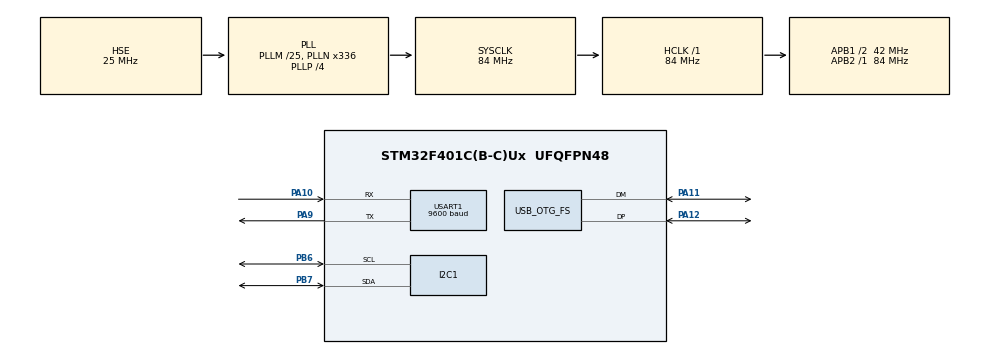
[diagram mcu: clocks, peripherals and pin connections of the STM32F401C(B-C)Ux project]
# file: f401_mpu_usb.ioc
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I2C1.I2C_Mode=I2C_Fast
Mcu.Family=STM32F4
Mcu.Name=STM32F401C(B-C)Ux
Mcu.Package=UFQFPN48
NVIC.OTG_FS_IRQn=true\:0\:0\:false\:false\:true\:false
NVIC.PriorityGroup=NVIC_PRIORITYGROUP_4
NVIC.USART1_IRQn=true\:0\:0\:false\:false\:true\:true
PA10.Mode=Asynchronous
PA10.Signal=USART1_RX
PA11.Mode=Device_Only
PA11.Signal=USB_OTG_FS_DM
PA12.Mode=Device_Only
PA12.Signal=USB_OTG_FS_DP
PA13.Mode=Serial_Wire
PA13.Signal=SYS_JTMS-SWDIO
PA14.Mode=Serial_Wire
PA14.Signal=SYS_JTCK-SWCLK
PA9.Mode=Asynchronous
PA9.Signal=USART1_TX
PB6.Mode=I2C
PB6.Signal=I2C1_SCL
PB7.Mode=I2C
PB7.Signal=I2C1_SDA
PH0\ -\ OSC_IN.Mode=HSE-External-Oscillator
PH0\ -\ OSC_IN.Signal=RCC_OSC_IN
PH1\ -\ OSC_OUT.Mode=HSE-External-Oscillator
PH1\ -\ OSC_OUT.Signal=RCC_OSC_OUT
ProjectManager.HeapSize=0x200
ProjectManager.StackSize=0x400
ProjectManager.TargetToolchain=SW4STM32
RCC.48MHZClocksFreq_Value=48000000
RCC.AHBFreq_Value=84000000
RCC.APB1CLKDivider=RCC_HCLK_DIV2
RCC.APB1Freq_Value=42000000
RCC.APB1TimFreq_Value=84000000
RCC.APB2Freq_Value=84000000
RCC.APB2TimFreq_Value=84000000
RCC.CortexFreq_Value=84000000
RCC.HCLKFreq_Value=84000000
RCC.HSE_VALUE=25000000
RCC.HSI_VALUE=16000000
RCC.LSE_VALUE=32768
RCC.PLLM=25
RCC.PLLN=336
RCC.PLLP=RCC_PLLP_DIV4
RCC.PLLQ=7
RCC.SYSCLKFreq_VALUE=84000000
RCC.SYSCLKSource=RCC_SYSCLKSOURCE_PLLCLK
RCC.VCOOutputFreq_Value=336000000
USART1.BaudRate=9600
USART1.VirtualMode=VM_ASYNC
USB_DEVICE.CLASS_NAME_FS=CDC
USB_DEVICE.VirtualMode=Cdc
USB_DEVICE.VirtualModeFS=Cdc_FS
USB_OTG_FS.VirtualMode=Device_Only
VP_USB_DEVICE_VS_USB_DEVICE_CDC_FS.Mode=CDC_FS
board=custom

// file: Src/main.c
/* USER CODE BEGIN Header */
/**
  ******************************************************************************
  * @file           : main.c
  * @brief          : Main program body
  ******************************************************************************
  * This notice applies to any and all portions of this file
  * that are not between comment pairs USER CODE BEGIN and
  * USER CODE END. Other portions of this file, whether
  * inserted by the user or by software development tools
  * are owned by their respective copyright owners.
  *
  * Copyright (c) 2020 STMicroelectronics International N.V.
  * All rights reserved.
  *
  * Redistribution and use in source and binary forms, with or without
  * modification, are permitted, provided that the following conditions are met:
  *
  * 1. Redistribution of source code must retain the above copyright notice,
  *    this list of conditions and the following disclaimer.
  * 2. Redistributions in binary form must reproduce the above copyright notice,
  *    this list of conditions and the following disclaimer in the documentation
  *    and/or other materials provided with the distribution.
  * 3. Neither the name of STMicroelectronics nor the names of other
  *    contributors to this software may be used to endorse or promote products
  *    derived from this software without specific written permission.
  * 4. This software, including modifications and/or derivative works of this
  *    software, must execute solely and exclusively on microcontroller or
  *    microprocessor devices manufactured by or for STMicroelectronics.
  * 5. Redistribution and use of this software other than as permitted under
  *    this license is void and will automatically terminate your rights under
  *    this license.
  *
  * THIS SOFTWARE IS PROVIDED BY STMICROELECTRONICS AND CONTRIBUTORS "AS IS"
  * AND ANY EXPRESS, IMPLIED OR STATUTORY WARRANTIES, INCLUDING, BUT NOT
  * LIMITED TO, THE IMPLIED WARRANTIES OF MERCHANTABILITY, FITNESS FOR A
  * PARTICULAR PURPOSE AND NON-INFRINGEMENT OF THIRD PARTY INTELLECTUAL PROPERTY
  * RIGHTS ARE DISCLAIMED TO THE FULLEST EXTENT PERMITTED BY LAW. IN NO EVENT
  * SHALL STMICROELECTRONICS OR CONTRIBUTORS BE LIABLE FOR ANY DIRECT, INDIRECT,
  * INCIDENTAL, SPECIAL, EXEMPLARY, OR CONSEQUENTIAL DAMAGES (INCLUDING, BUT NOT
  * LIMITED TO, PROCUREMENT OF SUBSTITUTE GOODS OR SERVICES; LOSS OF USE, DATA,
  * OR PROFITS; OR BUSINESS INTERRUPTION) HOWEVER CAUSED AND ON ANY THEORY OF
  * LIABILITY, WHETHER IN CONTRACT, STRICT LIABILITY, OR TORT (INCLUDING
  * NEGLIGENCE OR OTHERWISE) ARISING IN ANY WAY OUT OF THE USE OF THIS SOFTWARE,
  * EVEN IF ADVISED OF THE POSSIBILITY OF SUCH DAMAGE.
  *
  ******************************************************************************
  */
/* USER CODE END Header */

#include <usbd_cdc_if.h>
#include "main.h"
#include "i2c.h"
#include "usart.h"
#include "usb_device.h"
#include "gpio.h"
#include "math.h"

/* USER CODE BEGIN Includes */
//#include "mpu6050.h"
/* USER CODE END Includes */

/* USER CODE BEGIN PV */
//MPU6050_t MPU6050;
uint8_t start_buf[2];
char str_tx[16];
uint8_t buf_mes[82];
/* USER CODE END PV */

void SystemClock_Config(void);

void HAL_UART_RxCpltCallback(UART_HandleTypeDef *huart);

int main(void) {

    /* MCU Configuration--------------------------------------------------------*/

    /* Reset of all peripherals, Initializes the Flash interface and the Systick. */
    HAL_Init();

    /* Configure the system clock */
    SystemClock_Config();

    /* Initialize all configured peripherals */
    MX_GPIO_Init();
    MX_I2C1_Init();
    MX_USB_DEVICE_Init();
    MX_USART1_UART_Init();
    /* USER CODE BEGIN 2 */
//    while (MPU6050_Init(&hi2c1) == 1);
    /* USER CODE END 2 */
    /* Infinite loop */
    while (1) {

        /* USER CODE BEGIN 3 */

        HAL_UART_Receive_IT(&huart1, (uint8_t *) buf_mes, 81);
        CDC_Transmit_FS((uint8_t *) buf_mes, 81);
        HAL_Delay(5000);
        CDC_Transmit_FS((uint8_t *) "\r\n", 2);

//        sprintf(str_tx, "End transmit\r\n");
//        CDC_Transmit_FS((uint8_t *) str_tx, strlen(str_tx));
//        HAL_Delay(1000);
    }
    /* USER CODE END 3 */
}

void SystemClock_Config(void) {
    RCC_OscInitTypeDef RCC_OscInitStruct = {0};
    RCC_ClkInitTypeDef RCC_ClkInitStruct = {0};

    /**Configure the main internal regulator output voltage
    */
    __HAL_RCC_PWR_CLK_ENABLE();
    __HAL_PWR_VOLTAGESCALING_CONFIG(PWR_REGULATOR_VOLTAGE_SCALE2);
    /**Initializes the CPU, AHB and APB busses clocks
    */
    RCC_OscInitStruct.OscillatorType = RCC_OSCILLATORTYPE_HSE;
    RCC_OscInitStruct.HSEState = RCC_HSE_ON;
    RCC_OscInitStruct.PLL.PLLState = RCC_PLL_ON;
    RCC_OscInitStruct.PLL.PLLSource = RCC_PLLSOURCE_HSE;
    RCC_OscInitStruct.PLL.PLLM = 25;
    RCC_OscInitStruct.PLL.PLLN = 336;
    RCC_OscInitStruct.PLL.PLLP = RCC_PLLP_DIV4;
    RCC_OscInitStruct.PLL.PLLQ = 7;
    if (HAL_RCC_OscConfig(&RCC_OscInitStruct) != HAL_OK) {
        Error_Handler();
    }
    /**Initializes the CPU, AHB and APB busses clocks
    */
    RCC_ClkInitStruct.ClockType = RCC_CLOCKTYPE_HCLK | RCC_CLOCKTYPE_SYSCLK
                                  | RCC_CLOCKTYPE_PCLK1 | RCC_CLOCKTYPE_PCLK2;
    RCC_ClkInitStruct.SYSCLKSource = RCC_SYSCLKSOURCE_PLLCLK;
    RCC_ClkInitStruct.AHBCLKDivider = RCC_SYSCLK_DIV1;
    RCC_ClkInitStruct.APB1CLKDivider = RCC_HCLK_DIV2;
    RCC_ClkInitStruct.APB2CLKDivider = RCC_HCLK_DIV1;

    if (HAL_RCC_ClockConfig(&RCC_ClkInitStruct, FLASH_LATENCY_2) != HAL_OK) {
        Error_Handler();
    }
}

/* USER CODE BEGIN 4 */
void HAL_UART_RxCpltCallback(UART_HandleTypeDef *huart) {
    if (huart == &huart1) {

    }
}
/* USER CODE END 4 */

void Error_Handler(void) {
}

/************************ (C) COPYRIGHT STMicroelectronics *****END OF FILE****/
